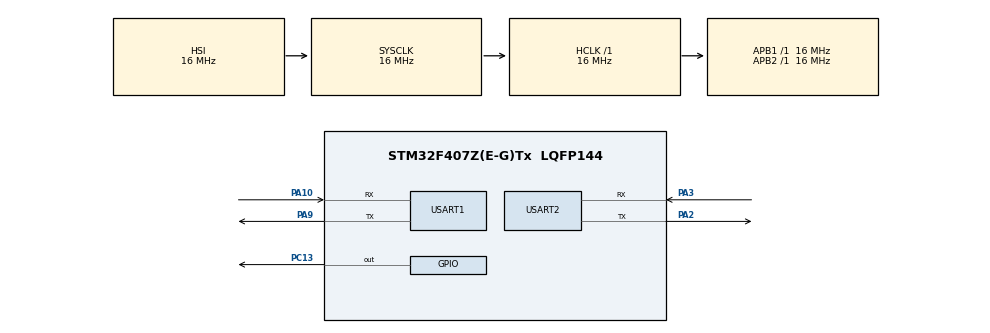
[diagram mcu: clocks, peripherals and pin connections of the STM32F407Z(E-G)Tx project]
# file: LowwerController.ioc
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Mcu.Family=STM32F4
Mcu.Name=STM32F407Z(E-G)Tx
Mcu.Package=LQFP144
NVIC.PriorityGroup=NVIC_PRIORITYGROUP_4
NVIC.USART2_IRQn=true\:0\:0\:false\:false\:true\:true\:true\:true
PA10.Mode=Asynchronous
PA10.Signal=USART1_RX
PA2.Mode=Asynchronous
PA2.Signal=USART2_TX
PA3.Mode=Asynchronous
PA3.Signal=USART2_RX
PA9.Mode=Asynchronous
PA9.Signal=USART1_TX
PC13-ANTI_TAMP.Signal=GPIO_Output
ProjectManager.HeapSize=0x200
ProjectManager.StackSize=0x400
ProjectManager.TargetToolchain=Makefile
RCC.AHBFreq_Value=16000000
RCC.APB1Freq_Value=16000000
RCC.APB2Freq_Value=16000000
RCC.CortexFreq_Value=16000000
RCC.HSE_VALUE=25000000
RCC.HSI_VALUE=16000000
RCC.LSE_VALUE=32768
RCC.SYSCLKFreq_VALUE=16000000
RCC.VCOOutputFreq_Value=192000000
USART1.VirtualMode=VM_ASYNC
USART2.VirtualMode=VM_ASYNC
board=custom

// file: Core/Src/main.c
/* USER CODE BEGIN Header */
/**
  ******************************************************************************
  * @file           : main.c
  * @brief          : Main program body
  ******************************************************************************
  * @attention
  *
  * Copyright (c) 2025 STMicroelectronics.
  * All rights reserved.
  *
  * This software is licensed under terms that can be found in the LICENSE file
  * in the root directory of this software component.
  * If no LICENSE file comes with this software, it is provided AS-IS.
  *
  ******************************************************************************
  */
/* USER CODE END Header */
#include "main.h"
#include "usart.h"
#include "gpio.h"

/* USER CODE BEGIN Includes */
#include "motor_ctrl.h"
/* USER CODE END Includes */

void SystemClock_Config(void);

/* USER CODE BEGIN 0 */

//TODO:测试ros2串口
/**
 * @brief  中断回调函数
 */
// void HAL_UART_RxCpltCallback(UART_HandleTypeDef *huart)
// {
//     if (huart->Instance == USART1)
//     {
//         if (rx_char == '\n' || rx_char == '\r' || rx_char == '!')
//         {
//             rx_buffer[rx_index] = '\0';
//             if (rx_index > 0)
//             {
//                 Motor_ParseDebug(rx_buffer);
//             }
//             rx_index = 0;
//         }
//         else
//         {
//             rx_buffer[rx_index++] = rx_char;
//             if (rx_index >= sizeof(rx_buffer))
//                 rx_index = 0;
//         }

//         HAL_UART_Receive_IT(&huart1, &rx_char, 1);
//     }
//     if (huart->Instance == USART2) {
//         rx_buffer[rx_index++] = rx_char;

//         if (rx_char == '\n') {
//             rx_buffer[rx_index] = '\0';
//             Process_Upper_Command(rx_buffer);
//             rx_index = 0;
//         }

//         HAL_UART_Receive_IT(&huart2, &rx_char, 1);
//     }
// }
/* USER CODE END 0 */

int main(void)
{

  /* MCU Configuration--------------------------------------------------------*/

  /* Reset of all peripherals, Initializes the Flash interface and the Systick. */
  HAL_Init();

  /* Configure the system clock */
  SystemClock_Config();

  /* Initialize all configured peripherals */
  MX_GPIO_Init();
  MX_USART1_UART_Init();
  MX_USART2_UART_Init();

  /* Infinite loop */
  /* USER CODE BEGIN WHILE */
  while (1)
  {
    Motor_OpenLoop(1,500,1000);
    HAL_Delay(1000);
    /* USER CODE END WHILE */

  }
}

void SystemClock_Config(void)
{
  RCC_OscInitTypeDef RCC_OscInitStruct = {0};
  RCC_ClkInitTypeDef RCC_ClkInitStruct = {0};

  /** Configure the main internal regulator output voltage
  */
  __HAL_RCC_PWR_CLK_ENABLE();
  __HAL_PWR_VOLTAGESCALING_CONFIG(PWR_REGULATOR_VOLTAGE_SCALE1);

  /** Initializes the RCC Oscillators according to the specified parameters
  * in the RCC_OscInitTypeDef structure.
  */
  RCC_OscInitStruct.OscillatorType = RCC_OSCILLATORTYPE_HSI;
  RCC_OscInitStruct.HSIState = RCC_HSI_ON;
  RCC_OscInitStruct.HSICalibrationValue = RCC_HSICALIBRATION_DEFAULT;
  RCC_OscInitStruct.PLL.PLLState = RCC_PLL_NONE;
  if (HAL_RCC_OscConfig(&RCC_OscInitStruct) != HAL_OK)
  {
    Error_Handler();
  }

  /** Initializes the CPU, AHB and APB buses clocks
  */
  RCC_ClkInitStruct.ClockType = RCC_CLOCKTYPE_HCLK|RCC_CLOCKTYPE_SYSCLK
                              |RCC_CLOCKTYPE_PCLK1|RCC_CLOCKTYPE_PCLK2;
  RCC_ClkInitStruct.SYSCLKSource = RCC_SYSCLKSOURCE_HSI;
  RCC_ClkInitStruct.AHBCLKDivider = RCC_SYSCLK_DIV1;
  RCC_ClkInitStruct.APB1CLKDivider = RCC_HCLK_DIV1;
  RCC_ClkInitStruct.APB2CLKDivider = RCC_HCLK_DIV1;

  if (HAL_RCC_ClockConfig(&RCC_ClkInitStruct, FLASH_LATENCY_0) != HAL_OK)
  {
    Error_Handler();
  }
}

void Error_Handler(void)
{
  __disable_irq();
  while (1)
  {
  }
}
